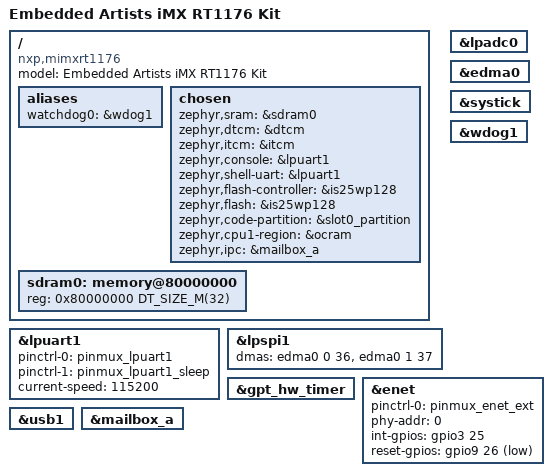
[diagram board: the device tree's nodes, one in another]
/*
 * Copyright 2024, Embedded Artists
 *
 * SPDX-License-Identifier: Apache-2.0
 */

/dts-v1/;

#include <nxp/nxp_rt11xx_cm7.dtsi>
#include "ea_rt1176_common.dtsi"

/ {
	model = "Embedded Artists iMX RT1176 Kit";
	compatible = "nxp,mimxrt1176";

	aliases {
		watchdog0 = &wdog1;
	};

	chosen {
		zephyr,sram = &sdram0;
		zephyr,dtcm = &dtcm;
		zephyr,itcm = &itcm;
		zephyr,console = &lpuart1;
		zephyr,shell-uart = &lpuart1;
		zephyr,flash-controller = &is25wp128;
		zephyr,flash = &is25wp128;
		zephyr,code-partition = &slot0_partition;
		zephyr,cpu1-region = &ocram;
		zephyr,ipc = &mailbox_a;
	};

	sdram0: memory@80000000 {
		device_type = "memory";
		reg = <0x80000000 DT_SIZE_M(32)>;
	};
};

&lpuart1 {
	status = "okay";
	pinctrl-0 = <&pinmux_lpuart1>;
	pinctrl-1 = <&pinmux_lpuart1_sleep>;
	pinctrl-names = "default", "sleep";
	current-speed = <115200>;
};

&lpspi1 {
	dmas = <&edma0 0 36>, <&edma0 1 37>;
	dma-names = "rx", "tx";
	status = "okay";
};

&lpadc0 {
	status = "okay";
};

&edma0 {
	status = "okay";
};

/* GPT and Systick are enabled. If power management is enabled, the GPT
 * timer will be used instead of systick, as allows the core clock to
 * be gated.
 */
&gpt_hw_timer {
	status = "okay";
};

&systick {
	status = "okay";
};

&wdog1 {
	status = "okay";
};

&enet {
	status = "okay";
	pinctrl-0 = <&pinmux_enet_ext>;
	pinctrl-names = "default";
	phy-addr = <0>;
	int-gpios = <&gpio3 25 GPIO_ACTIVE_HIGH>;
	reset-gpios = <&gpio9 26 GPIO_ACTIVE_LOW>;
};

zephyr_udc0: &usb1 {
	status = "okay";
};

&mailbox_a {
	status = "okay";
};
